# EMIF2 register map
Vendor: Texas Instruments
Registers are 32-bit, access per field, reset 0x0 unless marked. A register's access mark holds for its fields unless they carry their own. Offsets are as the file gives them; [hi:lo] are bit positions; {n}, {i} and the like mark numbered series; 'fields as' and 'values as' point back to an identical list.

## EMIF2 (part 2 of 2)
0xD4 EMIF_READ_WRITE_LEVELING_RAMP_WINDOW — Read/write leveling ramp window register
  [12:0] RDWRLVLINC_RMP_WIN rw — Incremental leveling ramp window in number of refresh periods. The value programmed is minus one the required value. Refresh period is defined by REFRESH_RATE inEMIF_SDRAM_REFRESH_CONTROL register. NOTE: Incremental leveling is not supported on this device.
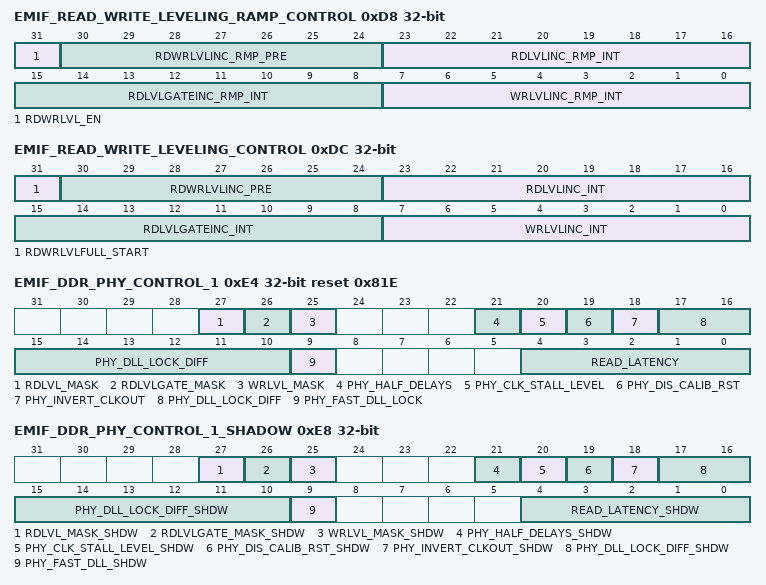
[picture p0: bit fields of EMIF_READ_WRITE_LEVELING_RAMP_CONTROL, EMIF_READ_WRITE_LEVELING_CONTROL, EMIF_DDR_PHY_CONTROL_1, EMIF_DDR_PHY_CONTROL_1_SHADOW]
0xD8 EMIF_READ_WRITE_LEVELING_RAMP_CONTROL rw — Read/write leveling ramp control register
  [31] RDWRLVL_EN — Read-Write Leveling enable. Set 1 to enable leveling. Set 0 to disable leveling.
  [30:24] RDWRLVLINC_RMP_PRE — Incremental leveling pre-scalar in number of refresh periods during ramp window. The value programmed is minus one the required value. Refresh period is defined by REFRESH_RATE inEMIF_SDRAM_REFRESH_CONTROL register. NOTE: Incremental leveling is not supported on this device.
  [23:16] RDLVLINC_RMP_INT — Incremental read data eye training interval during ramp window. Number of RDWRLVLINC_RMP_PRE intervals between incremental read data eye training during ramp window. A value of 0 will disable incremental read data eye training.NOTE: Incremental leveling is not supported on this device.
  [15:8] RDLVLGATEINC_RMP_INT — Incremental read DQS gate training interval during ramp window. Number of RDWRLVLINC_RMP_PRE intervals between incremental read DQS gate training during ramp window. A value of 0 will disable incremental read DQS gate training.NOTE: Incremental leveling is not supported on this device.
  [7:0] WRLVLINC_RMP_INT — Incremental write leveling interval during ramp window. Number of RDWRLVLINC_RMP_PRE intervals between incremental write leveling during ramp window. A value of 0 will disable incremental write leveling.NOTE: Incremental leveling is not supported on this device.
0xDC EMIF_READ_WRITE_LEVELING_CONTROL rw — Read/write leveling control register
  [31] RDWRLVLFULL_START — Full leveling trigger. Writing a 1 to this field triggers full read and write leveling. This bit will self clear to 0.
  [30:24] RDWRLVLINC_PRE — Incremental leveling pre-scalar in number of refresh periods. The value programmed is minus one the required value. Refresh period is defined by REFRESH_RATE inEMIF_SDRAM_REFRESH_CONTROL register. NOTE: Incremental leveling is not supported on this device.
  [23:16] RDLVLINC_INT — Incremental read data eye training interval. Number of RDWRLVLINC_PRE intervals between incremental read data eye training. A value of 0 will disable incremental read data eye training.NOTE: Incremental leveling is not supported on this device.
  [15:8] RDLVLGATEINC_INT — Incremental read DQS gate training interval. Number of RDWRLVLINC_PRE intervals between incremental read DQS gate training. A value of 0 will disable incremental read DQS gate training.NOTE: Incremental leveling is not supported on this device.
  [7:0] WRLVLINC_INT — Incremental write leveling interval. Number of RDWRLVLINC_PRE intervals between incremental write leveling. A value of 0 will disable incremental write leveling.NOTE: Incremental leveling is not supported on this device.
0xE4 EMIF_DDR_PHY_CONTROL_1 rw reset 0x81E — PHY control register 1
  [27] RDLVL_MASK — Writing a 1 to this field will mask read data eye training during full leveling command, plus drives reg_phy_use_rd_data_eye_level control low to allow user to use programmed ratio values.
  [26] RDLVLGATE_MASK — Writing a 1 to this field will mask dqs gate training during full leveling command, plus drives reg_phy_use_rd_dqs_level control low to allow user to use programmed ratio values.
  [25] WRLVL_MASK — Writing a 1 to this field will mask write leveling training during full leveling command, plus drives reg_phy_use_wr_level control low to allow user to use programmed ratio values.
  [21] PHY_HALF_DELAYS — Adjust slave delay line delays to support 2× mode 1: 2× mode (MDLL clock is half the rate of PHY) 0: 1× mode (MDLL clock rate is same as PHY)
  [20] PHY_CLK_STALL_LEVEL — Enable variable idle value for delay lines. Enable during normal operations to avoid differential aging in the delay lines.
  [19] PHY_DIS_CALIB_RST — Disable the dll_calib (internally generated) signal from resetting the Read Capture FIFO pointers and portions of data PHYs. Debug only. Note: dll_calib is generated by 1. EMIF_MISC_REG[0] DLL_CALIB_OS set to 1,or 2. by the PHY when it detects that the clock frequency variation has exceeded the bounds set by PHY_DLL_LOCK_DIFF or 3. periodically throughout the leveling process.
  [18] PHY_INVERT_CLKOUT — Inverts the polarity of DRAM clock. 0: core clock is passed on to DRAM 1: inverted core clock is passed on to DRAM
  [17:10] PHY_DLL_LOCK_DIFF — The maximum number of delay line taps variation while maintaining the master DLL lock. When the PHY is in locked state and the variation on the clock exceeds the variation indicated by this field, the lock signal is de-asserted and a dll_calib signal is generated. To prevent the dll_calib signal from being asserted in the middle of traffic when the clock jitter exceeds the variation, this register needs to be set to a value which will ensure that the lock will not be lost. Recommended value is 16.
  [9] PHY_FAST_DLL_LOCK — Controls master DLL to lock fast or average logic must be part of locking process. Set to 1 before OPP transition commences, and set back to 0 after OPP transition completes. 1: MDLL lock is asserted based on single sample 0: MDLL lock is asserted based on average of 16 samples.
  [4:0] READ_LATENCY — This field defines the read latency for the read data from SDRAM in number of DDR clock cycles. This field is used by the EMIF as well as the PHY. READ_LATENCY = RL + reg_phy_rdc_we_to_re -1. EMIF uses above equation to calculate reg_phy_rdc_we_to_re and forward it to the PHY. For DDR3, the true RL is used, not the decoded value. See JEDEC spec.
0xE8 EMIF_DDR_PHY_CONTROL_1_SHADOW rw
  [27] RDLVL_MASK_SHDW — Shadow field for RDLVL_MASK
  [26] RDLVLGATE_MASK_SHDW — Shadow field for RDLVLGATE_MASK
  [25] WRLVL_MASK_SHDW — Shadow field for WRLVL_MASK
  [21] PHY_HALF_DELAYS_SHDW — Shadow field for PHY_HALF_DELAYS
  [20] PHY_CLK_STALL_LEVEL_SHDW — Shadow field for PHY_CLK_STALL_LEVEL
  [19] PHY_DIS_CALIB_RST_SHDW — Shadow field for PHY_DIS_CALIB_RST
  [18] PHY_INVERT_CLKOUT_SHDW — Shadow field for PHY_INVERT_CLKOUT
  [17:10] PHY_DLL_LOCK_DIFF_SHDW — Shadow field for PHY_DLL_LOCK_DIFF
  [9] PHY_FAST_DLL_SHDW — Shadow field for PHY_FAST_DLL
  [4:0] READ_LATENCY_SHDW — Shadow field for READ_LATENCY
0xEC EMIF_DDR_PHY_CONTROL_2 rw
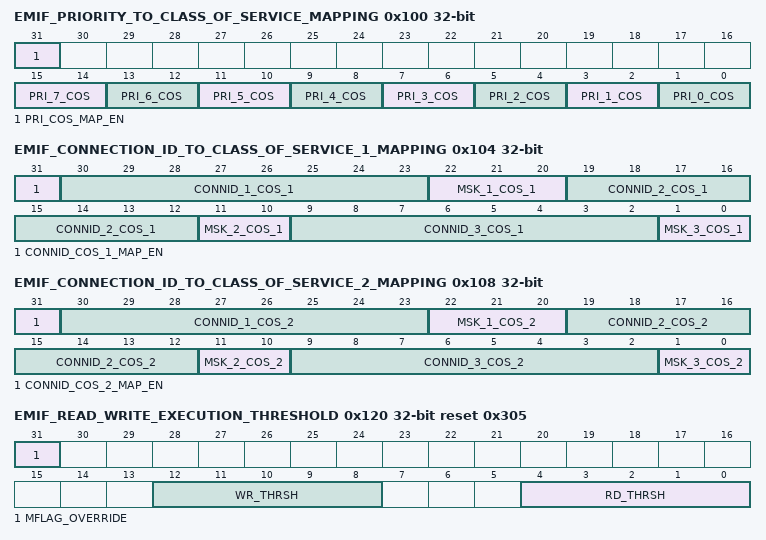
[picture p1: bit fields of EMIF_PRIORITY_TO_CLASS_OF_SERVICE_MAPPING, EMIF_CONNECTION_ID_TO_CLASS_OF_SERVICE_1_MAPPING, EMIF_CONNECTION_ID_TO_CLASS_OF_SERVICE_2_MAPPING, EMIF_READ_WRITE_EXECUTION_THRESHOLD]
0x100 EMIF_PRIORITY_TO_CLASS_OF_SERVICE_MAPPING
  [31] PRI_COS_MAP_EN rw — Set 1 to enable priority to class of service mapping. Set 0 to disable mapping.
  [2n+1:2n] PRI_{n}_COS rw (n=0..7) — Class of service for commands with priority of {n}. Value can be 1, 2, or 3. Setting a value of 0 will have similar effects as a value of 3.
0x104 EMIF_CONNECTION_ID_TO_CLASS_OF_SERVICE_1_MAPPING rw
  [31] CONNID_COS_1_MAP_EN — Set 1 to enable Connection ID to class of service 1 mapping. Set 0 to disable mapping.
  [30:23] CONNID_1_COS_1 — Connection ID value 1 for class of service 1.
  [22:20] MSK_1_COS_1 — Mask for Connection ID value 1 for class of service 1. Value of 0 will disable masking. Value of 1 will mask Connection ID bit 0. Value of 2 will mask Connection ID bits 1:0. Value of 3 will mask Connection ID bits 2:0. Value of 4 will mask Connection ID bits 3:0. Value of 5 will mask Connection ID bits 4:0. Value of 6 will mask Connection ID bits 5:0. Value of 7 will mask Connection ID bits 6:0.
  [19:12] CONNID_2_COS_1 — Connection ID value 2 for class of service 1.
  [11:10] MSK_2_COS_1 — Mask for Connection ID value 2 for class of service 1. Value of 0 will disable masking. Value of 1 will mask Connection ID bit 0. Value of 2 will mask Connection ID bits 1:0. Value of 3 will mask Connection ID bits 2:0.
  [9:2] CONNID_3_COS_1 — Connection ID value 3 for class of service 1.
  [1:0] MSK_3_COS_1 — Mask for Connection ID value 3 for class of service 1. Value of 0 will disable masking. Value of 1 will mask Connection ID bit 0. Value of 2 will mask Connection ID bits 1:0. Value of 3 will mask Connection ID bits 2:0.
0x108 EMIF_CONNECTION_ID_TO_CLASS_OF_SERVICE_2_MAPPING rw
  [31] CONNID_COS_2_MAP_EN — Set 1 to enable Connection ID to class of service 2 mapping. Set 0 to disable mapping.
  [30:23] CONNID_1_COS_2 — Connection ID value 1 for class of service 2.
  [22:20] MSK_1_COS_2 — Mask for Connection ID value 1 for class of service 2. Value of 0 will disable masking. Value of 1 will mask Connection ID bit 0. Value of 2 will mask Connection ID bits 1:0. Value of 3 will mask Connection ID bits 2:0. Value of 4 will mask Connection ID bits 3:0. Value of 5 will mask Connection ID bits 4:0. Value of 6 will mask Connection ID bits 5:0. Value of 7 will mask Connection ID bits 6:0.
  [19:12] CONNID_2_COS_2 — Connection ID value 2 for class of service 2.
  [11:10] MSK_2_COS_2 — Mask for Connection ID value 2 for class of service 2. Value of 0 will disable masking. Value of 1 will mask Connection ID bit 0. Value of 2 will mask Connection ID bits 1:0. Value of 3 will mask Connection ID bits 2:0.
  [9:2] CONNID_3_COS_2 — Connection ID value 3 for class of service 2.
  [1:0] MSK_3_COS_2 — Mask for Connection ID value 3 for class of service 2. Value of 0 will disable masking. Value of 1 will mask Connection ID bit 0. Value of 2 will mask Connection ID bits 1:0. Value of 3 will mask Connection ID bits 2:0.
0x120 EMIF_READ_WRITE_EXECUTION_THRESHOLD reset 0x305
  [31] MFLAG_OVERRIDE rw
    0=use_MFLAG; 1=use_COS (Use Priority Class of Service)
  [12:8] WR_THRSH rw — Write Threshold. Number of SDRAM write bursts after which the EMIF arbitration will switch to executing read commands. The value programmed is always minus one the required number
  [4:0] RD_THRSH ro — Read threshold. Number of SDRAM read bursts after which the EMIF arbitration will switch to executing write commands. The value that is programmed is always minus one the required number
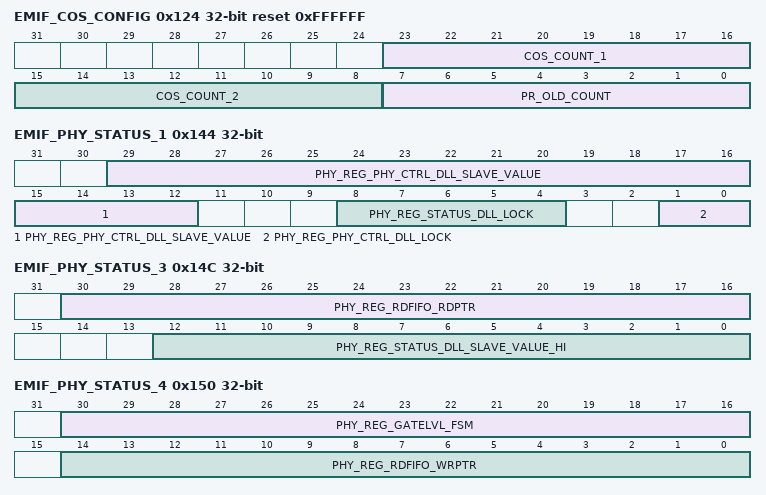
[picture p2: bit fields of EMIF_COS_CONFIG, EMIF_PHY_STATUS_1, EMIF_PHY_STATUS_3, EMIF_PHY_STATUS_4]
0x124 EMIF_COS_CONFIG reset 0xFFFFFF — Priority Raise Counter Register.
  [23:16] COS_COUNT_1 rw — Priority Raise Counter for class of service 1. Number of EMIF_FICLK cycles after which the EMIF momentarily raises the priority of the class of service 1 commands in the Command FIFO. A value of N will be equal to N x 16 clocks.
  [15:8] COS_COUNT_2 rw — Priority Raise Counter for class of service 2. Number of EMIF_FICLK cycles after which the EMIF momentarily raises the priority of the class of service 2 commands in the Command FIFO. A value of N will be equal to N x 16 clocks.
  [7:0] PR_OLD_COUNT rw — Priority Raise Old Counter. Number of EMIF_FICLK cycles after which the EMIF momentarily raises the priority of the oldest command in the Command FIFO. A value of N will be equal to N x 16 clocks.
0x144 EMIF_PHY_STATUS_1 ro
  [29:12] PHY_REG_PHY_CTRL_DLL_SLAVE_VALUE — DLL Slave Value
  [8:4] PHY_REG_STATUS_DLL_LOCK — Lock Status for Data DLLs
  [1:0] PHY_REG_PHY_CTRL_DLL_LOCK — Lock Status for Command DLLs
0x148 EMIF_PHY_STATUS_2 ro
  [31:0] PHY_REG_STATUS_DLL_SLAVE_VALUE_LO — Bits 31:0 of Phy_reg_status_dll_slave_value
0x14C EMIF_PHY_STATUS_3 ro
  [30:16] PHY_REG_RDFIFO_RDPTR — Read FIFO Read Pointer
  [12:0] PHY_REG_STATUS_DLL_SLAVE_VALUE_HI — Bits 44:32 of Phy_reg_status_dll_slave_value
0x150 EMIF_PHY_STATUS_4 ro
  [30:16] PHY_REG_GATELVL_FSM — Gate Leveling FSM
  [14:0] PHY_REG_RDFIFO_WRPTR — Read FIFO Write Pointer
0x154 EMIF_PHY_STATUS_5 ro
  [19:0] PHY_REG_RD_LEVEL_FSM — Read Leveling FSM
0x158 EMIF_PHY_STATUS_6 ro
  [14:0] PHY_REG_WR_LEVEL_FSM — Write Leveling FSM
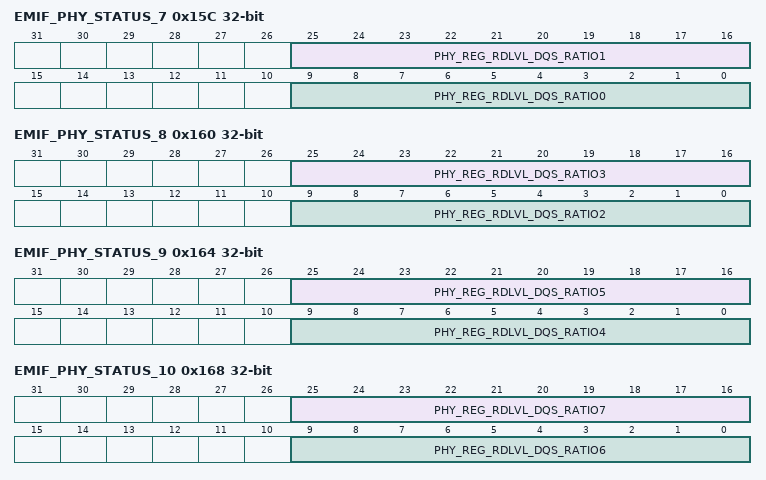
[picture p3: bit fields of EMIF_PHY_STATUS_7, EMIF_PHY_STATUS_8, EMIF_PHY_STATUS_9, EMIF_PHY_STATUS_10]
0x15C EMIF_PHY_STATUS_7 ro
  [25:16] PHY_REG_RDLVL_DQS_RATIO1 — Read leveling DQS ratio1
  [9:0] PHY_REG_RDLVL_DQS_RATIO0 — Read leveling DQS ratio0
0x160 EMIF_PHY_STATUS_8 ro
  [25:16] PHY_REG_RDLVL_DQS_RATIO3 — Read leveling DQS ratio3
  [9:0] PHY_REG_RDLVL_DQS_RATIO2 — Read leveling DQS ratio2
0x164 EMIF_PHY_STATUS_9 ro
  [25:16] PHY_REG_RDLVL_DQS_RATIO5 — Read Leveling DQS ratio5
  [9:0] PHY_REG_RDLVL_DQS_RATIO4 — Read Leveling DQS ratio4
0x168 EMIF_PHY_STATUS_10 ro
  [25:16] PHY_REG_RDLVL_DQS_RATIO7 — Read leveling DQS ratio7
  [9:0] PHY_REG_RDLVL_DQS_RATIO6 — Read leveling DQS ratio6
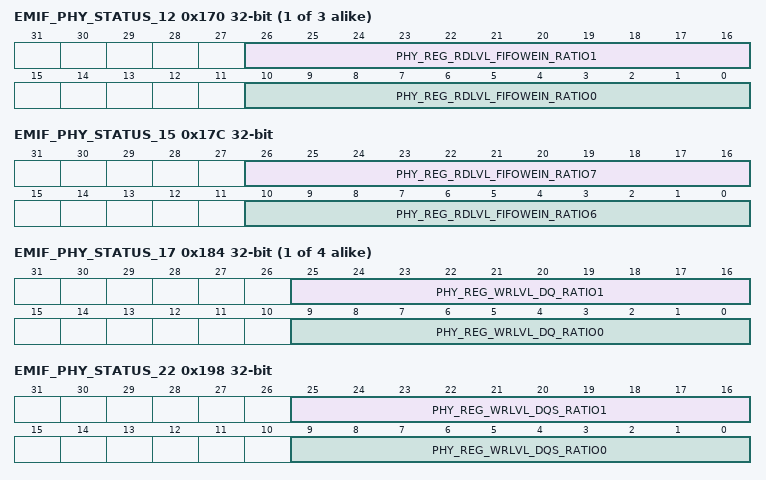
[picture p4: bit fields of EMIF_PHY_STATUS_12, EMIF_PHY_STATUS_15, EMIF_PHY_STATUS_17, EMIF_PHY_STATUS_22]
{0x140+4i} EMIF_PHY_STATUS_{i} ro (i=12..14)
  [26:16] PHY_REG_RDLVL_FIFOWEIN_RATIO{2i-23} — Read leveling FIFO Write Enable Ratio{2i-23}
  [10:0] PHY_REG_RDLVL_FIFOWEIN_RATIO{2i-24} — Read leveling FIFO Write Enable Ratio{2i-24}
0x17C EMIF_PHY_STATUS_15 ro
  [26:16] PHY_REG_RDLVL_FIFOWEIN_RATIO7 — Read leveling FIFO Wrie Enable Ratio7
  [10:0] PHY_REG_RDLVL_FIFOWEIN_RATIO6 — Read leveling FIFO Wrie Enable Ratio6
{0x140+4i} EMIF_PHY_STATUS_{i} ro (i=17..20)
  [25:16] PHY_REG_WRLVL_DQ_RATIO{2i-33} — Write leveling DQ ratio{2i-33}
  [9:0] PHY_REG_WRLVL_DQ_RATIO{2i-34} — Write leveling DQ ratio{2i-34}
0x198 EMIF_PHY_STATUS_22 ro
  [25:16] PHY_REG_WRLVL_DQS_RATIO1 — Write leveling DQS ratio 1
  [9:0] PHY_REG_WRLVL_DQS_RATIO0 — Write leveling DQS ratio 0
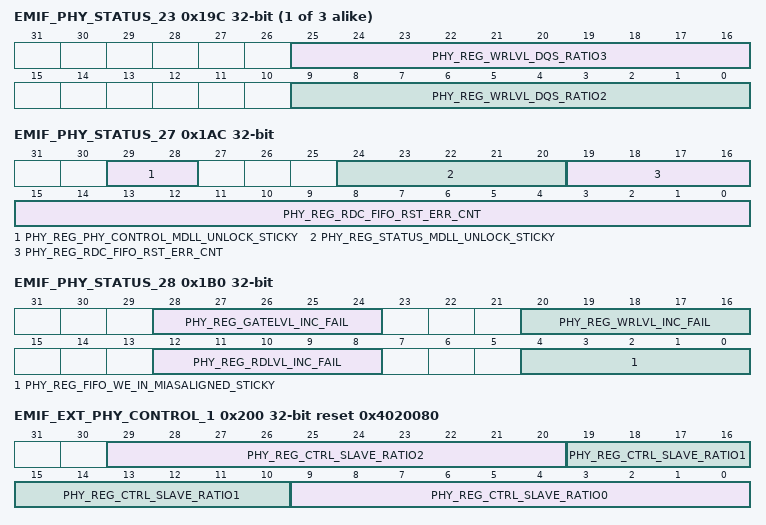
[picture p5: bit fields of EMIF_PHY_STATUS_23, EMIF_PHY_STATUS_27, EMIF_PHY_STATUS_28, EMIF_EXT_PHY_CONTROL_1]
{0x140+4i} EMIF_PHY_STATUS_{i} ro (i=23..25)
  [25:16] PHY_REG_WRLVL_DQS_RATIO{2i-43} — Write leveling DQS ratio{2i-43}
  [9:0] PHY_REG_WRLVL_DQS_RATIO{2i-44} — Write leveling DQS ratio{2i-44}
0x1AC EMIF_PHY_STATUS_27 ro
  [29:28] PHY_REG_PHY_CONTROL_MDLL_UNLOCK_STICKY — Phy control MDLL unlock sticky
  [24:20] PHY_REG_STATUS_MDLL_UNLOCK_STICKY — Phy data MDLL unlock sticky
  [19:0] PHY_REG_RDC_FIFO_RST_ERR_CNT — RDC FIFO reset error count
0x1B0 EMIF_PHY_STATUS_28 ro
  [28:24] PHY_REG_GATELVL_INC_FAIL — Gate leveling failure.NOTE: Incremental leveling is not supported on this device.
  [20:16] PHY_REG_WRLVL_INC_FAIL — Write leveling failure.NOTE: Incremental leveling is not supported on this device.
  [12:8] PHY_REG_RDLVL_INC_FAIL — Read leveling failure.NOTE: Incremental leveling is not supported on this device.
  [4:0] PHY_REG_FIFO_WE_IN_MIASALIGNED_STICKY — FIFO write enable in misaligned stickly
0x200 EMIF_EXT_PHY_CONTROL_1 reset 0x4020080 — Control DLL Slave Ratio Register
  [29:20] PHY_REG_CTRL_SLAVE_RATIO2 rw — The user programmable ratio value for address/command launch timing in PHY control macro 2. This is the fraction of a clock cycle in units of 256ths. In other words, the full-cycle tap value from the master DLL will be scaled by this number over 256 to get the delay value for the slave delay line.
  [19:10] PHY_REG_CTRL_SLAVE_RATIO1 rw — The user programmable ratio value for address/command launch timing in PHY control macro 1. This is the fraction of a clock cycle in units of 256ths. In other words, the full-cycle tap value from the master DLL will be scaled by this number over 256 to get the delay value for the slave delay line. Set to:
  [9:0] PHY_REG_CTRL_SLAVE_RATIO0 rw — The user programmable ratio value for address/command launch timing in PHY control macro 0. This is the fraction of a clock cycle in units of 256ths. In other words, the full-cycle tap value from the master DLL will be scaled by this number over 256 to get the delay value for the slave delay line. Set to:
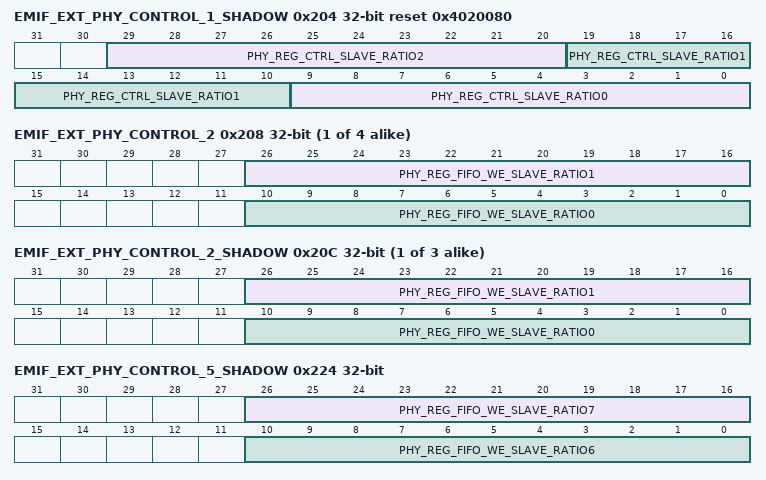
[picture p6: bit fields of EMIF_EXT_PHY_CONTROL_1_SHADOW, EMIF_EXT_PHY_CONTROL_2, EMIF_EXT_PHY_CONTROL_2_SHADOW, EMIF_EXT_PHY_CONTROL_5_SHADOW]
0x204 EMIF_EXT_PHY_CONTROL_1_SHADOW reset 0x4020080 — Control DLL Slave Ratio Shadow Register. Its value is loaded in register on any frequency change.
  fields as EMIF_EXT_PHY_CONTROL_1
{0x1F8+8i} EMIF_EXT_PHY_CONTROL_{i} (i=2..5) — Data macro {i-2}, FIFO write enable (read DQS gate) DLL Slave Ratio Register
  [26:16] PHY_REG_FIFO_WE_SLAVE_RATIO{2i-3} rw — The user programmable ratio value for the FIFO write enable slave DLL in PHY data macro {i-2}, chip select 1. This is the fraction of a clock cycle in units of 256ths. In other words, the full-cycle tap value from the master DLL will be scaled by this number over 256 to get the delay value for the slave delay line. NOTE: Chip select 1 is not supported on this device.
  [10:0] PHY_REG_FIFO_WE_SLAVE_RATIO{2i-4} rw — The user programmable ratio value for the FIFO write enable slave DLL in PHY data macro {i-2}, chip select 0. This is the fraction of a clock cycle in units of 256ths. In other words, the full-cycle tap value from the master DLL will be scaled by this number over 256 to get the delay value for the slave delay line.
{0x1FC+8i} EMIF_EXT_PHY_CONTROL_{i}_SHADOW (i=2..4) — Data macro {i-2}, FIFO write enable (read DQS gate) DLL Slave Ratio Shadow Register. Its value is loaded in register on any frequency change.
  fields as EMIF_EXT_PHY_CONTROL_2
0x224 EMIF_EXT_PHY_CONTROL_5_SHADOW — Data macro 3, FIFO write enable (read DQS gate) DLL Slave Ratio Register. Its value is loaded in register on any frequency change.
  [26:16] PHY_REG_FIFO_WE_SLAVE_RATIO7 rw — The user programmable ratio value for the FIFO write enable slave DLL in PHY data macro 3, chip select 1. This is the fraction of a clock cycle in units of 256ths. In other words, the full-cycle tap value from the master DLL will be scaled by this number over 256 to get the delay value for the slave delay line. NOTE: Chip select 1 is not supported on this device.
  [10:0] PHY_REG_FIFO_WE_SLAVE_RATIO6 rw — The user programmable ratio value for the FIFO write enable slave DLL in PHY data macro 3, chip select 0. This is the fraction of a clock cycle in units of 256ths. In other words, the full-cycle tap value from the master DLL will be scaled by this number over 256 to get the delay value for the slave delay line.
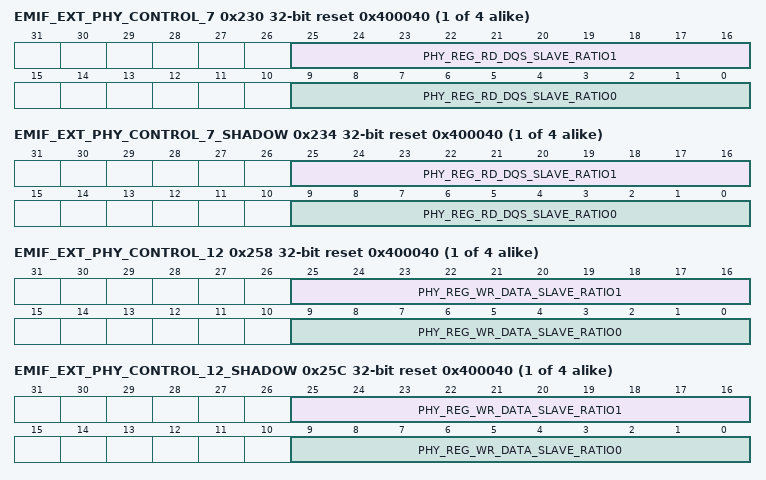
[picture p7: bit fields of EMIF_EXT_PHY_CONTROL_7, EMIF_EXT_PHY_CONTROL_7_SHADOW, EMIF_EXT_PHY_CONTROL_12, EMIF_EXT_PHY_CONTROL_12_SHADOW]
{0x1F8+8i} EMIF_EXT_PHY_CONTROL_{i} reset 0x400040 (i=7..10) — Data macro {i-7}, read DQS DLL Slave Ratio Register
  [25:16] PHY_REG_RD_DQS_SLAVE_RATIO{2i-13} rw — The user programmable ratio value for the read DQS slave DLL in PHY data macro {i-7}, chip select 1. This is the fraction of a clock cycle in units of 256ths. In other words, the full-cycle tap value from the master DLL will be scaled by this number over 256 to get the delay value for the slave delay line. NOTE: Chip select 1 is not supported on this device.
  [9:0] PHY_REG_RD_DQS_SLAVE_RATIO{2i-14} rw — The user programmable ratio value for the read DQS slave DLL in PHY data macro {i-7}, chip select 0. This is the fraction of a clock cycle in units of 256ths. In other words, the full-cycle tap value from the master DLL will be scaled by this number over 256 to get the delay value for the slave delay line.
{0x1FC+8i} EMIF_EXT_PHY_CONTROL_{i}_SHADOW reset 0x400040 (i=7..10) — Data macro {i-7}, read DQS DLL Slave Ratio Shadow Register. Its value is loaded in register on any frequency change.
  fields as EMIF_EXT_PHY_CONTROL_7
{0x1F8+8i} EMIF_EXT_PHY_CONTROL_{i} reset 0x400040 (i=12..15) — Data macro {i-12}, write DQ (data) DLL Slave Ratio Register
  [25:16] PHY_REG_WR_DATA_SLAVE_RATIO{2i-23} rw — The user programmable ratio value for the write DQ slave DLL in PHY data macro {i-12}, chip select 1. This is the fraction of a clock cycle in units of 256ths. In other words, the full-cycle tap value from the master DLL will be scaled by this number over 256 to get the delay value for the slave delay line. NOTE: Chip select 1 is not supported on this device.
  [9:0] PHY_REG_WR_DATA_SLAVE_RATIO{2i-24} rw — The user programmable ratio value for the write DQ slave DLL in PHY data macro {i-12}, chip select 0. This is the fraction of a clock cycle in units of 256ths. In other words, the full-cycle tap value from the master DLL will be scaled by this number over 256 to get the delay value for the slave delay line.
{0x1FC+8i} EMIF_EXT_PHY_CONTROL_{i}_SHADOW reset 0x400040 (i=12..15) — Data macro {i-12}, write DQ (data) DLL Slave Ratio Shadow Register. Its value is loaded in register on any frequency change.
  fields as EMIF_EXT_PHY_CONTROL_12
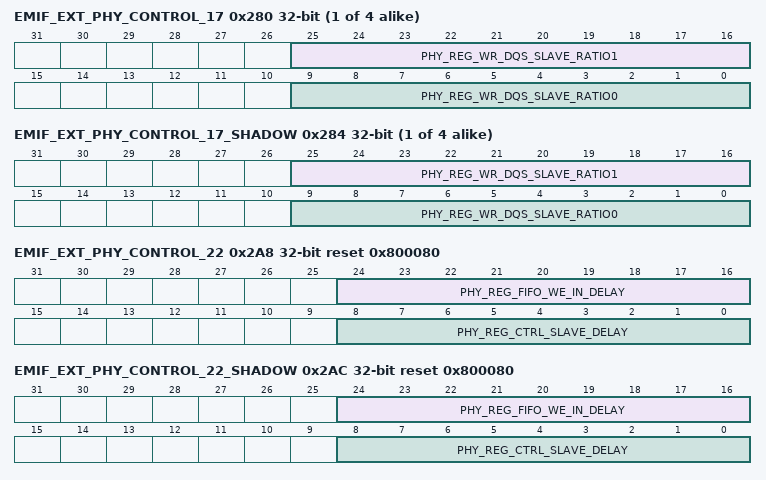
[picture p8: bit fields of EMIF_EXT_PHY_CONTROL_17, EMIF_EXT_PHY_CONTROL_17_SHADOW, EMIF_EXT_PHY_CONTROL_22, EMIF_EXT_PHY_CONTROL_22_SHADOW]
{0x1F8+8i} EMIF_EXT_PHY_CONTROL_{i} (i=17..20) — Data macro {i-17}, write DQS DLL Slave Ratio Register
  [25:16] PHY_REG_WR_DQS_SLAVE_RATIO{2i-33} rw — The user programmable ratio value for the write DQS slave DLL in PHY data macro {i-17}, chip select 1. This is the fraction of a clock cycle in units of 256ths. In other words, the full-cycle tap value from the master DLL will be scaled by this number over 256 to get the delay value for the slave delay line. NOTE: Chip select 1 is not supported on this device.
  [9:0] PHY_REG_WR_DQS_SLAVE_RATIO{2i-34} rw — The user programmable ratio value for the write DQS slave DLL in PHY data macro {i-17}, chip select 0. This is the fraction of a clock cycle in units of 256ths. In other words, the full-cycle tap value from the master DLL will be scaled by this number over 256 to get the delay value for the slave delay line.
{0x1FC+8i} EMIF_EXT_PHY_CONTROL_{i}_SHADOW (i=17..20) — Data macro {i-17}, write DQS DLL Slave Ratio Shadow Register. Its value is loaded in register on any frequency change.
  fields as EMIF_EXT_PHY_CONTROL_17
0x2A8 EMIF_EXT_PHY_CONTROL_22 reset 0x800080
  [24:16] PHY_REG_FIFO_WE_IN_DELAY rw — The user programmable FIFO write enable delay value used when DLL_OVERRIDE = 1.
  [8:0] PHY_REG_CTRL_SLAVE_DELAY rw — The user programmable command delay value used when DLL_OVERRIDE = 1.
0x2AC EMIF_EXT_PHY_CONTROL_22_SHADOW reset 0x800080
  fields as EMIF_EXT_PHY_CONTROL_22
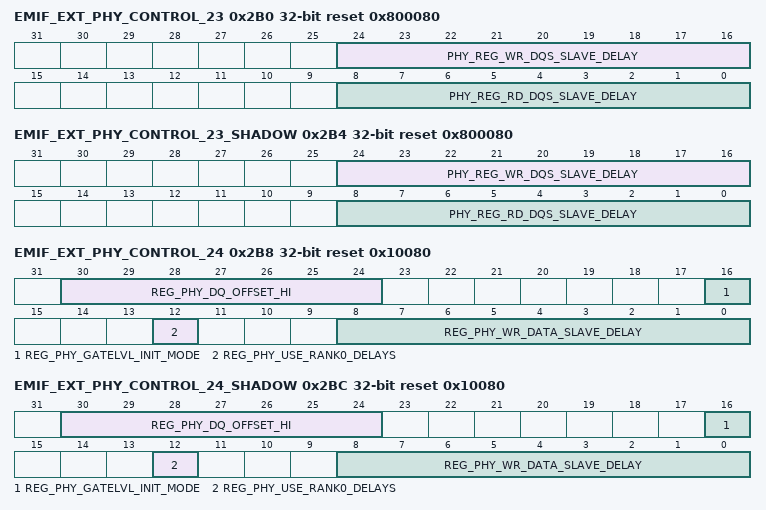
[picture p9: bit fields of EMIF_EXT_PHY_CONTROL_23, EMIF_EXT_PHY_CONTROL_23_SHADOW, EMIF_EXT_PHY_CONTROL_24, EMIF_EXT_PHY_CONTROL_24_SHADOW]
0x2B0 EMIF_EXT_PHY_CONTROL_23 reset 0x800080
  [24:16] PHY_REG_WR_DQS_SLAVE_DELAY rw — The user programmable write DQS delay value used when DLL_OVERRIDE = 1.
  [8:0] PHY_REG_RD_DQS_SLAVE_DELAY rw — The user programmable read DQS delay value used when DLL_OVERRIDE = 1.
0x2B4 EMIF_EXT_PHY_CONTROL_23_SHADOW reset 0x800080
  fields as EMIF_EXT_PHY_CONTROL_23
0x2B8 EMIF_EXT_PHY_CONTROL_24 reset 0x10080
  [30:24] REG_PHY_DQ_OFFSET_HI rw — The user programmable offset ratio value from write DQS to write DQ. This value is used for the write DQ slave DLL in PHY ECC data macro. The ratio represents the fraction of a clock cycle in units of 256ths. In other words, the full-cycle tap value from the master DLL will be scaled by this number over 256 (in addition to the write DQS delay) to get the delay value for the slave delay line.
  [16] REG_PHY_GATELVL_INIT_MODE rw — The user programmable init ratio selection mode. Recommended value is 0x1.
  [12] REG_PHY_USE_RANK0_DELAYS rw — Delay selection. Chip select 0 delay line ratios are used for all chip selects when set to 1. Each chip select uses its own delays when set to 0.
  [8:0] REG_PHY_WR_DATA_SLAVE_DELAY rw — The user programmable write DQ delay value used when DLL_OVERRIDE = 1.
0x2BC EMIF_EXT_PHY_CONTROL_24_SHADOW reset 0x10080
  fields as EMIF_EXT_PHY_CONTROL_24
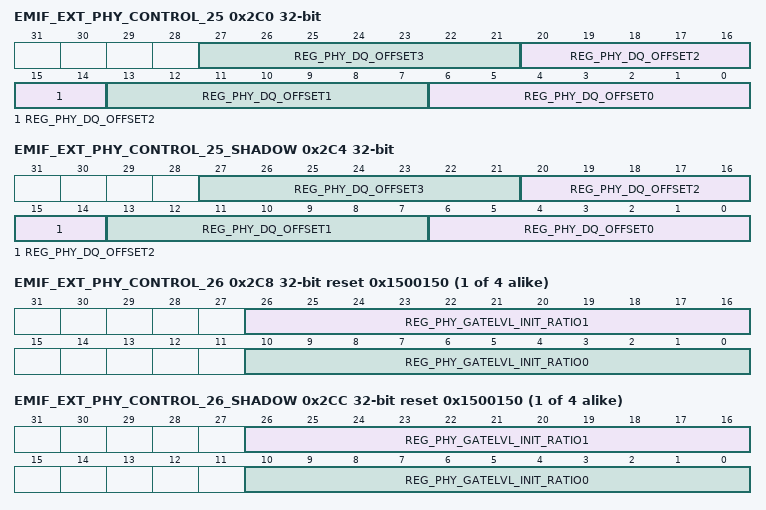
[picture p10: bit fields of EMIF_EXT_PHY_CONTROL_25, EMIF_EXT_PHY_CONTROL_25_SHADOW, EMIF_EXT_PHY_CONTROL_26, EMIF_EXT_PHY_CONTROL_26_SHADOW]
0x2C0 EMIF_EXT_PHY_CONTROL_25 — DQ DLL Slave Ratio Offset Register
  [7n+6:7n] REG_PHY_DQ_OFFSET{n} rw (n=0..3) — The user programmable offset ratio value from write DQS to write DQ. This value is used for the write DQ slave DLL in PHY data macro {n}. The ratio represents the fraction of a clock cycle in units of 256ths. In other words, the full-cycle tap value from the master DLL will be scaled by this number over 256 (in addition to the write DQS delay) to get the delay value for the slave delay line.
0x2C4 EMIF_EXT_PHY_CONTROL_25_SHADOW — DQ DLL Slave Ratio Offset Shadow Register. Its value is loaded in register on any frequency change.
  fields as EMIF_EXT_PHY_CONTROL_25
{0x1F8+8i} EMIF_EXT_PHY_CONTROL_{i} reset 0x1500150 (i=26..29) — Data macro {i-26}, FIFO write enable (read DQS gate) DLL Slave Init Ratio Register
  [26:16] REG_PHY_GATELVL_INIT_RATIO{2i-51} rw — The user programmable initialization ratio value used by the gate training finite state machine (hardware leveling) for the FIFO write enable slave DLL in PHY data macro {i-26}, chip select 1. This is the fraction of a clock cycle in units of 256ths. In other words, the full-cycle tap value from the master DLL will be scaled by this number over 256 to get the delay value for the slave delay line. NOTE: Chip select 1 is not supported on this device.
  [10:0] REG_PHY_GATELVL_INIT_RATIO{2i-52} rw — The user programmable initialization ratio value used by the gate training finite state machine (hardware leveling) for the FIFO write enable slave DLL in PHY data macro {i-26}, chip select 0. This is the fraction of a clock cycle in units of 256ths. In other words, the full-cycle tap value from the master DLL will be scaled by this number over 256 to get the delay value for the slave delay line.
{0x1FC+8i} EMIF_EXT_PHY_CONTROL_{i}_SHADOW reset 0x1500150 (i=26..29) — Data macro {i-26}, FIFO write enable (read DQS gate) DLL Slave Init Ratio Shadow Register. Its value is loaded in register on any frequency change.
  fields as EMIF_EXT_PHY_CONTROL_26
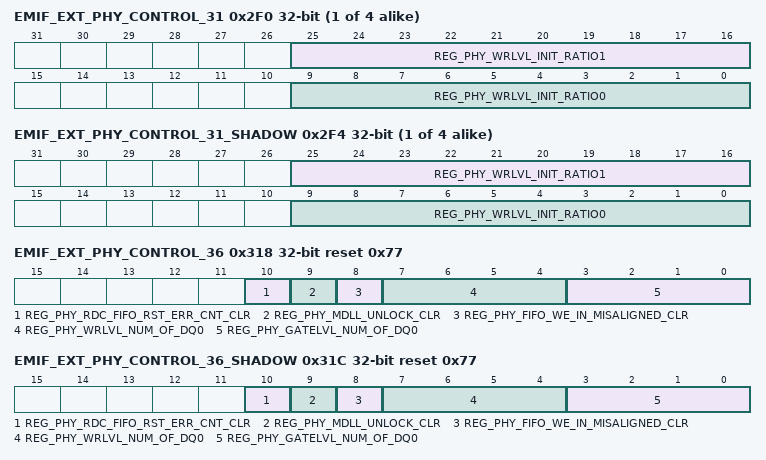
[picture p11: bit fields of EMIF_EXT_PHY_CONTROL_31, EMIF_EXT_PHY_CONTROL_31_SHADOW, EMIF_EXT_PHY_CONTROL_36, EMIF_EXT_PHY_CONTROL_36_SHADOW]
{0x1F8+8i} EMIF_EXT_PHY_CONTROL_{i} (i=31..34) — Data macro {i-31}, write DQS DLL Slave Init Ratio Register
  [25:16] REG_PHY_WRLVL_INIT_RATIO{2i-61} rw — The user programmable initialization ratio value used by the write leveling finite state machine (hardware leveling) for the write DQS slave DLL in PHY data macro {i-31}, chip select 1. This is the fraction of a clock cycle in units of 256ths. In other words, the full-cycle tap value from the master DLL will be scaled by this number over 256 to get the delay value for the slave delay line. NOTE: Chip select 1 is not supported on this device.
  [9:0] REG_PHY_WRLVL_INIT_RATIO{2i-62} rw — The user programmable initialization ratio value used by the write leveling finite state machine (hardware leveling) for the write DQS slave DLL in PHY data macro {i-31}, chip select 0. This is the fraction of a clock cycle in units of 256ths. In other words, the full-cycle tap value from the master DLL will be scaled by this number over 256 to get the delay value for the slave delay line.
{0x1FC+8i} EMIF_EXT_PHY_CONTROL_{i}_SHADOW (i=31..34) — Data macro {i-31}, write DQS DLL Slave Init Ratio Shadow Register. Its value is loaded in register on any frequency change.
  fields as EMIF_EXT_PHY_CONTROL_31
0x318 EMIF_EXT_PHY_CONTROL_36 reset 0x77
  [10] REG_PHY_RDC_FIFO_RST_ERR_CNT_CLR rw — Clear/reset the phy_reg_rdc_fifo_rst_err_cnt, phy_reg_rdfifo_wrptr and phy_reg_rdfifo_rdptr status flags. A value of 0x1 clears the flag. A value of 0x0 has no effect.
  [9] REG_PHY_MDLL_UNLOCK_CLR rw — Clears the phy_reg_status_mdll_unlock_sticky flag. A value of 0x1 clears the flag. A value of 0x0 has no effect.
  [8] REG_PHY_FIFO_WE_IN_MISALIGNED_CLR rw — Clears the phy_reg_fifo_we_in_misaligned_sticky status flag. A value of 0x1 clears the flag. A value of 0x0 has no effect.
  [7:4] REG_PHY_WRLVL_NUM_OF_DQ0 rw — Determines the number of samples fordq0_in for each ratio increment by the write leveling finite state machine (hardware leveling). The minimum value supported is 3; however, the default setting of 7 is recommended.
  [3:0] REG_PHY_GATELVL_NUM_OF_DQ0 rw — Determines the number of samples fordq0_in for each ratio increment by the gate training finite state machine (hardware leveling). The minimum value supported is 3; however, the default setting of 7 is recommended.
0x31C EMIF_EXT_PHY_CONTROL_36_SHADOW reset 0x77
  fields as EMIF_EXT_PHY_CONTROL_36
